# AVR128DB64 register map
Vendor: Atmel; File version: 1.0
CPU: other r0p0, little endian, no MPU, no FPU, 4 interrupt priority bits
Registers are 8-bit, read-write, reset 0x0 unless marked. A register's access mark holds for its fields unless they carry their own. Offsets are from the block's base; [hi:lo] are bit positions.

## CLKCTRL — Clock controller
Base 0x00800060
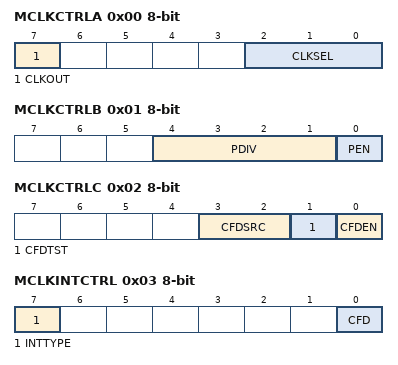
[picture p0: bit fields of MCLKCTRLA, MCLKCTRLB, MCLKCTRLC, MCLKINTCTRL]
0x00 MCLKCTRLA — MCLK Control A
  [7] CLKOUT — System clock out
  [2:0] CLKSEL — Clock select
    0=OSCHF (Internal high-frequency oscillator); 1=OSC32K (Internal 32.768 kHz oscillator); 2=XOSC32K (32.768 kHz crystal oscillator); 3=EXTCLK (External clock)
0x01 MCLKCTRLB — MCLK Control B
  [4:1] PDIV — Prescaler division
    0=2X; 1=4X; 2=8X; 3=16X; 4=32X; 5=64X; 8=6X; 9=10X; 10=12X; 11=24X; 12=48X
  [0] PEN — Prescaler enable
0x02 MCLKCTRLC — MCLK Control C
  [3:2] CFDSRC — Clock Failure Detect Source
    0=CLKMAIN (Main Clock); 1=XOSCHF; 2=XOSC32K
  [1] CFDTST wo — Clock Failure Detect Test
  [0] CFDEN — Clock Failure Detect Enable
0x03 MCLKINTCTRL — MCLK Interrupt Control
  [7] INTTYPE — Interrupt type
    0=INT (Regular Interrupt); 1=NMI
  [0] CFD — Clock Failure Detect Interrupt Enable
0x04 MCLKINTFLAGS — MCLK Interrupt Flags
  [0] CFD — Clock Failure Detect Interrupt Flag
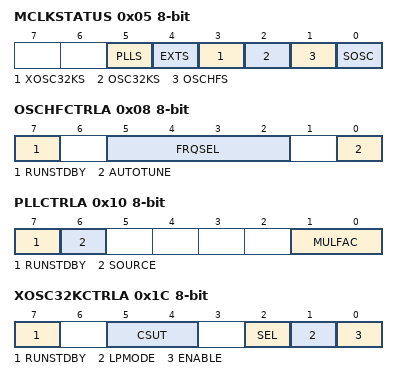
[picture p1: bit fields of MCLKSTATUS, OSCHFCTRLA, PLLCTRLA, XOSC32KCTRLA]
0x05 MCLKSTATUS
  [5] PLLS — PLL oscillator status
  [4] EXTS — External Clock status
  [3] XOSC32KS — 32.768 kHz Crystal Oscillator status
  [2] OSC32KS — 32KHz oscillator status
  [1] OSCHFS — High frequency oscillator status
  [0] SOSC — System Oscillator changing
0x08 OSCHFCTRLA — OSCHF Control A
  [7] RUNSTDBY — Run standby
  [5:2] FRQSEL — Frequency select
    0=1M (1 MHz system clock); 1=2M (2 MHz system clock); 2=3M (3 MHz system clock); 3=4M (4 MHz system clock (default)); 5=8M (8 MHz system clock); 6=12M (12 MHz system clock); 7=16M (16 MHz system clock); 8=20M (20 MHz system clock); 9=24M (24 MHz system clock)
  [0] AUTOTUNE
0x09 OSCHFTUNE
  [7:0] TUNE
0x10 PLLCTRLA — PLL Control A
  [7] RUNSTDBY — Run standby
  [6] SOURCE
    0=OSCHF (High frequency internal oscillator as PLL source); 1=XOSCHF (High frequency external clock or external high frequency oscillator as PLL source)
  [1:0] MULFAC — Multiplication factor
    0=DISABLE (PLL is disabled); 1=2x (2 x multiplication factor); 2=3x (3 x multiplication factor)
0x18 OSC32KCTRLA — OSC32K Control A
  [7] RUNSTDBY — Run standby
0x1C XOSC32KCTRLA — XOSC32K Control A
  [7] RUNSTDBY — Run standby
  [5:4] CSUT — Crystal startup time
    0=1K (1k cycles); 1=16K (16k cycles); 2=32K (32k cycles); 3=64K (64k cycles)
  [2] SEL — Select
  [1] LPMODE — Low power mode
  [0] ENABLE
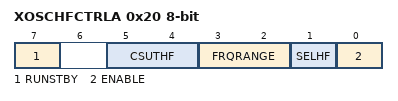
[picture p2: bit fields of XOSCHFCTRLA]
0x20 XOSCHFCTRLA — XOSC High-Frequency Control A
  [7] RUNSTBY — Run Standby
  [5:4] CSUTHF — Start-up Time Select
    0=256 XOSCHF cycles; 1=1K (1K XOSCHF cycles); 2=4K (4K XOSCHF cycles)
  [3:2] FRQRANGE — Frequency Range
    0=8M (Max 8 MHz XTAL Frequency); 1=16M (Max 16 MHz XTAL Frequency); 2=24M (Max 24 MHz XTAL Frequency); 3=32M (Max 32 MHz XTAL Frequency)
  [1] SELHF — External Source Select
    0=XTAL (External Crystal); 1=EXTCLOCK (External clock on XTALHF1 pin)
  [0] ENABLE

## CPU
Base 0x00800034
0x00 CCP — Configuration Change Protection
  [7:0] CCP — CCP signature
    157=SPM (SPM Instruction Protection); 216=IOREG (IO Register Protection)
0x07 RAMPZ — Extended Z-pointer Register
  [0] RAMPZ — Extended Z-Pointer Address bits
0x09 SP 16-bit (reset mask 0xFF) — Stack Pointer
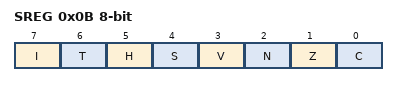
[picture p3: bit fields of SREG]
0x0B SREG — Status Register
  [7] I — Global Interrupt Enable Flag
  [6] T — Transfer Bit
  [5] H — Half Carry Flag
  [4] S — N Exclusive Or V Flag
  [3] V — Two's Complement Overflow Flag
  [2] N — Negative Flag
  [1] Z — Zero Flag
  [0] C — Carry Flag

## CPUINT — Interrupt Controller
Base 0x00800110
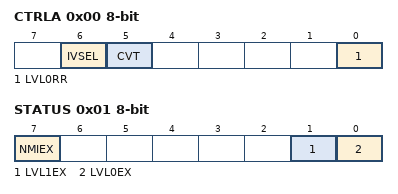
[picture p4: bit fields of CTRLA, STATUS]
0x00 CTRLA — Control A
  [6] IVSEL — Interrupt Vector Select
  [5] CVT — Compact Vector Table
  [0] LVL0RR — Round-robin Scheduling Enable
0x01 STATUS ro
  [7] NMIEX — Non-maskable Interrupt Executing
  [1] LVL1EX — Level 1 Interrupt Executing
  [0] LVL0EX — Level 0 Interrupt Executing
0x02 LVL0PRI — Interrupt Level 0 Priority
  [7:0] LVL0PRI — Interrupt Level Priority
0x03 LVL1VEC — Interrupt Level 1 Priority Vector
  [7:0] LVL1VEC — Interrupt Vector with High Priority
